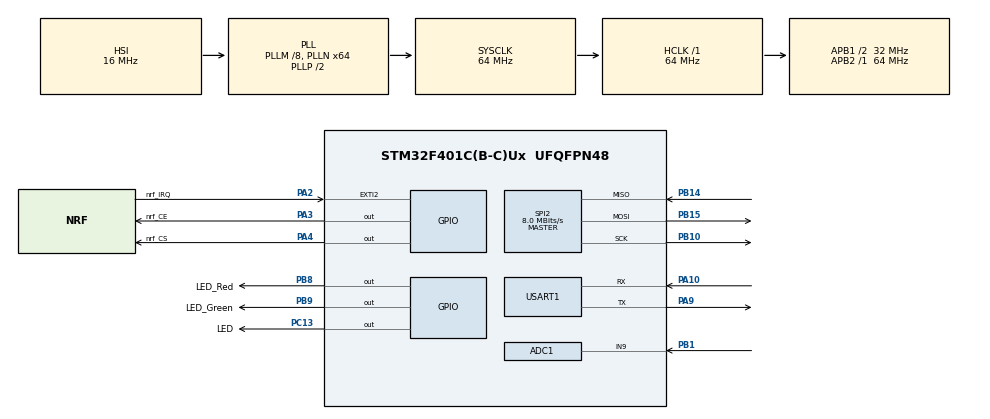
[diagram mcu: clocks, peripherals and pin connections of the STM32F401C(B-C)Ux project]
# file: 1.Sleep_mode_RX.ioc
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ADC1.Channel-0\#ChannelRegularConversion=ADC_CHANNEL_9
ADC1.NbrOfConversionFlag=1
ADC1.Rank-0\#ChannelRegularConversion=1
ADC1.SamplingTime-0\#ChannelRegularConversion=ADC_SAMPLETIME_3CYCLES
ADC1.master=1
Mcu.Family=STM32F4
Mcu.Name=STM32F401C(B-C)Ux
Mcu.Package=UFQFPN48
NVIC.ADC_IRQn=true\:0\:0\:false\:false\:true\:true\:true\:true
NVIC.EXTI2_IRQn=true\:0\:0\:false\:false\:true\:true\:true\:true
NVIC.PriorityGroup=NVIC_PRIORITYGROUP_4
PA10.Mode=Asynchronous
PA10.Signal=USART1_RX
PA13.Mode=Serial_Wire
PA13.Signal=SYS_JTMS-SWDIO
PA14.Mode=Serial_Wire
PA14.Signal=SYS_JTCK-SWCLK
PA2.GPIO_Label=nrf_IRQ
PA2.GPIO_ModeDefaultEXTI=GPIO_MODE_IT_FALLING
PA2.Signal=GPXTI2
PA3.GPIO_Label=nrf_CE
PA3.Signal=GPIO_Output
PA4.GPIO_Label=nrf_CS
PA4.Signal=GPIO_Output
PA9.Mode=Asynchronous
PA9.Signal=USART1_TX
PB1.Signal=ADCx_IN9
PB10.Mode=Full_Duplex_Master
PB10.Signal=SPI2_SCK
PB14.Mode=Full_Duplex_Master
PB14.Signal=SPI2_MISO
PB15.Mode=Full_Duplex_Master
PB15.Signal=SPI2_MOSI
PB8.GPIO_Label=LED_Red
PB8.Signal=GPIO_Output
PB9.GPIO_Label=LED_Green
PB9.Signal=GPIO_Output
PC13-ANTI_TAMP.GPIO_Label=LED
PC13-ANTI_TAMP.Signal=GPIO_Output
ProjectManager.HeapSize=0x200
ProjectManager.StackSize=0x400
ProjectManager.TargetToolchain=STM32CubeIDE
RCC.48MHZClocksFreq_Value=32000000
RCC.AHBFreq_Value=64000000
RCC.APB1CLKDivider=RCC_HCLK_DIV2
RCC.APB1Freq_Value=32000000
RCC.APB1TimFreq_Value=64000000
RCC.APB2Freq_Value=64000000
RCC.APB2TimFreq_Value=64000000
RCC.CortexFreq_Value=64000000
RCC.HCLKFreq_Value=64000000
RCC.HSE_VALUE=25000000
RCC.HSI_VALUE=16000000
RCC.LSE_VALUE=32768
RCC.PLLM=8
RCC.PLLN=64
RCC.SYSCLKFreq_VALUE=64000000
RCC.SYSCLKSource=RCC_SYSCLKSOURCE_PLLCLK
RCC.VCOOutputFreq_Value=128000000
SH.ADCx_IN9.0=ADC1_IN9,IN9
SPI2.BaudRatePrescaler=SPI_BAUDRATEPRESCALER_4
SPI2.CalculateBaudRate=8.0 MBits/s
SPI2.Direction=SPI_DIRECTION_2LINES
SPI2.Mode=SPI_MODE_MASTER
SPI2.VirtualType=VM_MASTER
USART1.VirtualMode=VM_ASYNC
board=custom

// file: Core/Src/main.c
/* USER CODE BEGIN Header */
/**
  ******************************************************************************
  * @file           : main.c
  * @brief          : Main program body
  ******************************************************************************
  * @attention
  *
  * Copyright (c) 2024 STMicroelectronics.
  * All rights reserved.
  *
  * This software is licensed under terms that can be found in the LICENSE file
  * in the root directory of this software component.
  * If no LICENSE file comes with this software, it is provided AS-IS.
  *
  ******************************************************************************
  */
/* USER CODE END Header */
#include "main.h"

/* USER CODE BEGIN Includes */

#include "nrf24L01/nrf24L01.h"
#include "stm32f4xx_hal.h"
#include "stm32f4xx_hal_gpio.h"
/* USER CODE END Includes */

/* USER CODE BEGIN PD */
#define ON 1
#define OFF 0

// Define wake up period

/* USER CODE END PD */

ADC_HandleTypeDef hadc1;

SPI_HandleTypeDef hspi2;

UART_HandleTypeDef huart1;

void SystemClock_Config(void);
static void MX_GPIO_Init(void);
static void MX_USART1_UART_Init(void);
static void MX_SPI2_Init(void);
static void MX_ADC1_Init(void);

int main(void)
{

  /* MCU Configuration--------------------------------------------------------*/

  /* Reset of all peripherals, Initializes the Flash interface and the Systick. */
  HAL_Init();

  /* Configure the system clock */
  SystemClock_Config();

  /* Initialize all configured peripherals */
  MX_GPIO_Init();
  MX_USART1_UART_Init();
  MX_SPI2_Init();
  MX_ADC1_Init();
  /* USER CODE BEGIN 2 */

  NRF24_init_RX(1,1,1,1,1,1,1,1,1);
  /* USER CODE END 2 */

  /* Infinite loop */
  /* USER CODE BEGIN WHILE */
  while (1)
  {
	 NRF24L01_Receive();

    /* USER CODE END WHILE */

  }
}

void SystemClock_Config(void)
{
  RCC_OscInitTypeDef RCC_OscInitStruct = {0};
  RCC_ClkInitTypeDef RCC_ClkInitStruct = {0};

  /** Configure the main internal regulator output voltage
  */
  __HAL_RCC_PWR_CLK_ENABLE();
  __HAL_PWR_VOLTAGESCALING_CONFIG(PWR_REGULATOR_VOLTAGE_SCALE2);

  /** Initializes the RCC Oscillators according to the specified parameters
  * in the RCC_OscInitTypeDef structure.
  */
  RCC_OscInitStruct.OscillatorType = RCC_OSCILLATORTYPE_HSI;
  RCC_OscInitStruct.HSIState = RCC_HSI_ON;
  RCC_OscInitStruct.HSICalibrationValue = RCC_HSICALIBRATION_DEFAULT;
  RCC_OscInitStruct.PLL.PLLState = RCC_PLL_ON;
  RCC_OscInitStruct.PLL.PLLSource = RCC_PLLSOURCE_HSI;
  RCC_OscInitStruct.PLL.PLLM = 8;
  RCC_OscInitStruct.PLL.PLLN = 64;
  RCC_OscInitStruct.PLL.PLLP = RCC_PLLP_DIV2;
  RCC_OscInitStruct.PLL.PLLQ = 4;
  if (HAL_RCC_OscConfig(&RCC_OscInitStruct) != HAL_OK)
  {
    Error_Handler();
  }

  /** Initializes the CPU, AHB and APB buses clocks
  */
  RCC_ClkInitStruct.ClockType = RCC_CLOCKTYPE_HCLK|RCC_CLOCKTYPE_SYSCLK
                              |RCC_CLOCKTYPE_PCLK1|RCC_CLOCKTYPE_PCLK2;
  RCC_ClkInitStruct.SYSCLKSource = RCC_SYSCLKSOURCE_PLLCLK;
  RCC_ClkInitStruct.AHBCLKDivider = RCC_SYSCLK_DIV1;
  RCC_ClkInitStruct.APB1CLKDivider = RCC_HCLK_DIV2;
  RCC_ClkInitStruct.APB2CLKDivider = RCC_HCLK_DIV1;

  if (HAL_RCC_ClockConfig(&RCC_ClkInitStruct, FLASH_LATENCY_2) != HAL_OK)
  {
    Error_Handler();
  }
}

static void MX_ADC1_Init(void)
{

  ADC_ChannelConfTypeDef sConfig = {0};

  /** Configure the global features of the ADC (Clock, Resolution, Data Alignment and number of conversion)
  */
  hadc1.Instance = ADC1;
  hadc1.Init.ClockPrescaler = ADC_CLOCK_SYNC_PCLK_DIV2;
  hadc1.Init.Resolution = ADC_RESOLUTION_12B;
  hadc1.Init.ScanConvMode = DISABLE;
  hadc1.Init.ContinuousConvMode = DISABLE;
  hadc1.Init.DiscontinuousConvMode = DISABLE;
  hadc1.Init.ExternalTrigConvEdge = ADC_EXTERNALTRIGCONVEDGE_NONE;
  hadc1.Init.ExternalTrigConv = ADC_SOFTWARE_START;
  hadc1.Init.DataAlign = ADC_DATAALIGN_RIGHT;
  hadc1.Init.NbrOfConversion = 1;
  hadc1.Init.DMAContinuousRequests = DISABLE;
  hadc1.Init.EOCSelection = ADC_EOC_SINGLE_CONV;
  if (HAL_ADC_Init(&hadc1) != HAL_OK)
  {
    Error_Handler();
  }

  /** Configure for the selected ADC regular channel its corresponding rank in the sequencer and its sample time.
  */
  sConfig.Channel = ADC_CHANNEL_9;
  sConfig.Rank = 1;
  sConfig.SamplingTime = ADC_SAMPLETIME_3CYCLES;
  if (HAL_ADC_ConfigChannel(&hadc1, &sConfig) != HAL_OK)
  {
    Error_Handler();
  }

}

static void MX_SPI2_Init(void)
{

  /* SPI2 parameter configuration*/
  hspi2.Instance = SPI2;
  hspi2.Init.Mode = SPI_MODE_MASTER;
  hspi2.Init.Direction = SPI_DIRECTION_2LINES;
  hspi2.Init.DataSize = SPI_DATASIZE_8BIT;
  hspi2.Init.CLKPolarity = SPI_POLARITY_LOW;
  hspi2.Init.CLKPhase = SPI_PHASE_1EDGE;
  hspi2.Init.NSS = SPI_NSS_SOFT;
  hspi2.Init.BaudRatePrescaler = SPI_BAUDRATEPRESCALER_4;
  hspi2.Init.FirstBit = SPI_FIRSTBIT_MSB;
  hspi2.Init.TIMode = SPI_TIMODE_DISABLE;
  hspi2.Init.CRCCalculation = SPI_CRCCALCULATION_DISABLE;
  hspi2.Init.CRCPolynomial = 10;
  if (HAL_SPI_Init(&hspi2) != HAL_OK)
  {
    Error_Handler();
  }

}

static void MX_USART1_UART_Init(void)
{

  huart1.Instance = USART1;
  huart1.Init.BaudRate = 115200;
  huart1.Init.WordLength = UART_WORDLENGTH_8B;
  huart1.Init.StopBits = UART_STOPBITS_1;
  huart1.Init.Parity = UART_PARITY_NONE;
  huart1.Init.Mode = UART_MODE_TX_RX;
  huart1.Init.HwFlowCtl = UART_HWCONTROL_NONE;
  huart1.Init.OverSampling = UART_OVERSAMPLING_16;
  if (HAL_UART_Init(&huart1) != HAL_OK)
  {
    Error_Handler();
  }

}

static void MX_GPIO_Init(void)
{
  GPIO_InitTypeDef GPIO_InitStruct = {0};

  /* GPIO Ports Clock Enable */
  __HAL_RCC_GPIOC_CLK_ENABLE();
  __HAL_RCC_GPIOA_CLK_ENABLE();
  __HAL_RCC_GPIOB_CLK_ENABLE();

  /*Configure GPIO pin Output Level */
  HAL_GPIO_WritePin(LED_GPIO_Port, LED_Pin, GPIO_PIN_RESET);

  /*Configure GPIO pin Output Level */
  HAL_GPIO_WritePin(GPIOA, nrf_CE_Pin|nrf_CS_Pin, GPIO_PIN_RESET);

  /*Configure GPIO pin Output Level */
  HAL_GPIO_WritePin(GPIOB, LED_Red_Pin|LED_Green_Pin, GPIO_PIN_RESET);

  /*Configure GPIO pin : LED_Pin */
  GPIO_InitStruct.Pin = LED_Pin;
  GPIO_InitStruct.Mode = GPIO_MODE_OUTPUT_PP;
  GPIO_InitStruct.Pull = GPIO_NOPULL;
  GPIO_InitStruct.Speed = GPIO_SPEED_FREQ_LOW;
  HAL_GPIO_Init(LED_GPIO_Port, &GPIO_InitStruct);

  /*Configure GPIO pin : nrf_IRQ_Pin */
  GPIO_InitStruct.Pin = nrf_IRQ_Pin;
  GPIO_InitStruct.Mode = GPIO_MODE_IT_FALLING;
  GPIO_InitStruct.Pull = GPIO_NOPULL;
  HAL_GPIO_Init(nrf_IRQ_GPIO_Port, &GPIO_InitStruct);

  /*Configure GPIO pins : nrf_CE_Pin nrf_CS_Pin */
  GPIO_InitStruct.Pin = nrf_CE_Pin|nrf_CS_Pin;
  GPIO_InitStruct.Mode = GPIO_MODE_OUTPUT_PP;
  GPIO_InitStruct.Pull = GPIO_NOPULL;
  GPIO_InitStruct.Speed = GPIO_SPEED_FREQ_LOW;
  HAL_GPIO_Init(GPIOA, &GPIO_InitStruct);

  /*Configure GPIO pins : LED_Red_Pin LED_Green_Pin */
  GPIO_InitStruct.Pin = LED_Red_Pin|LED_Green_Pin;
  GPIO_InitStruct.Mode = GPIO_MODE_OUTPUT_PP;
  GPIO_InitStruct.Pull = GPIO_NOPULL;
  GPIO_InitStruct.Speed = GPIO_SPEED_FREQ_LOW;
  HAL_GPIO_Init(GPIOB, &GPIO_InitStruct);

  /* EXTI interrupt init*/
  HAL_NVIC_SetPriority(EXTI2_IRQn, 0, 0);
  HAL_NVIC_EnableIRQ(EXTI2_IRQn);

}

/* USER CODE BEGIN 4 */

void HAL_GPIO_EXTI_Callback(uint16_t GPIO_Pin)
{
	if(GPIO_Pin == GPIO_PIN_2)
	{
		IRQ_Callback();
	}
	else
	{
		__NOP();
	}

}

/* USER CODE END 4 */

void Error_Handler(void)
{
  __disable_irq();
  while (1)
  {
  }
}
